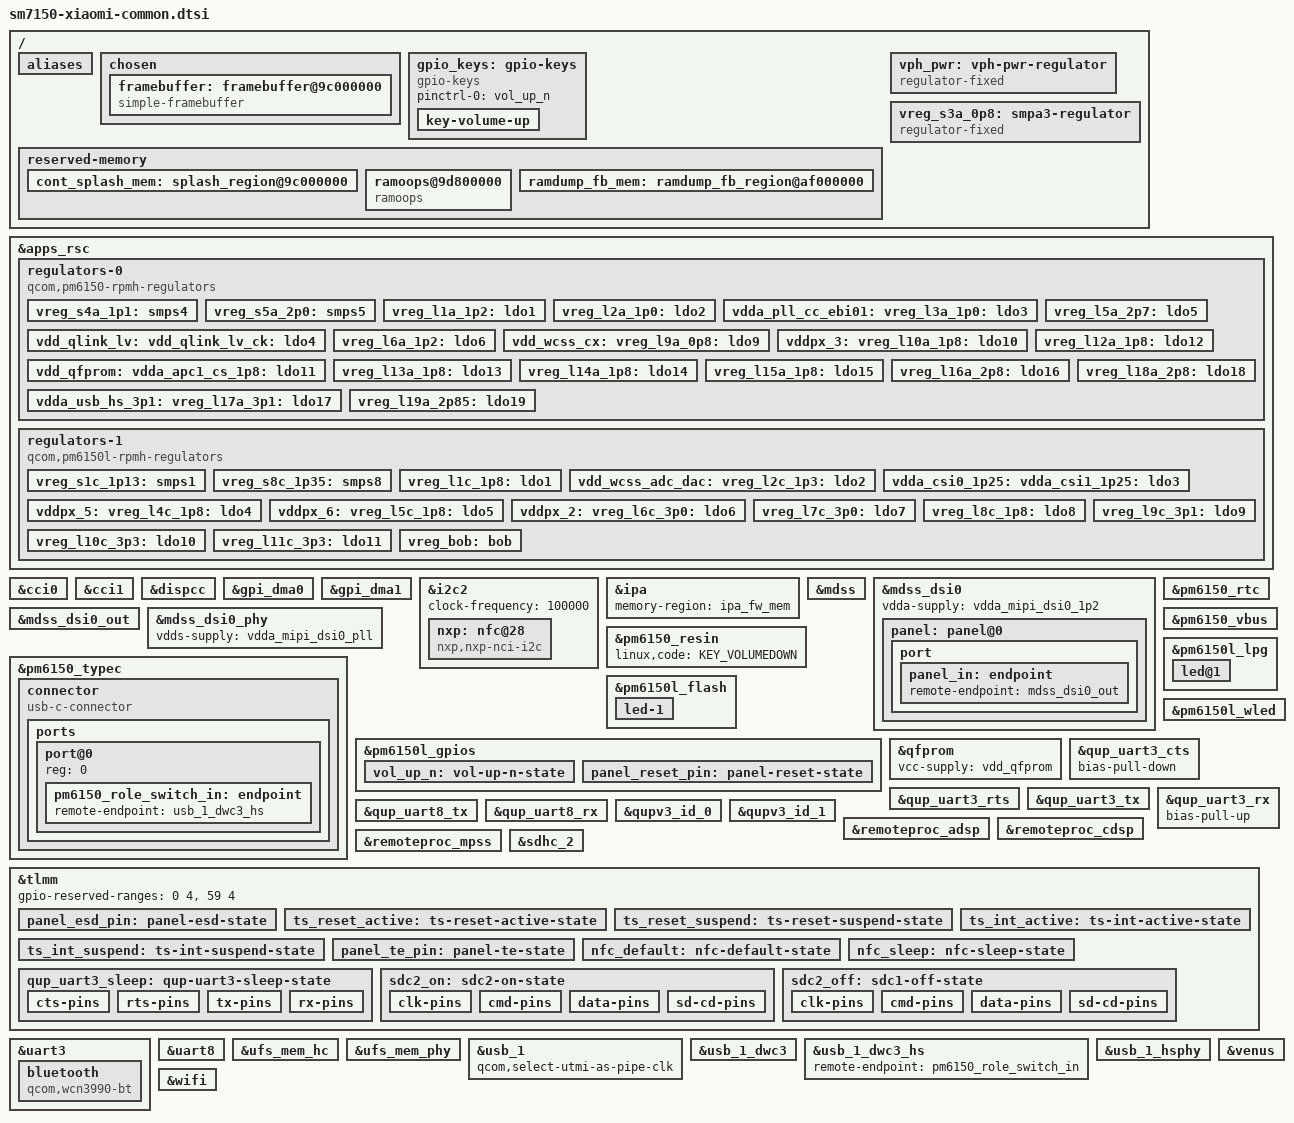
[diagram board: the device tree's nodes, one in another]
// SPDX-License-Identifier: BSD-3-Clause
/*
 * Copyright (c) 2024, Danila Tikhonov <danila@jiaxyga.com>
 * Copyright (c) 2024, David Wronek <davidwronek@gmail.com>
 * Copyright (c) 2024, Jens Reidel <adrian@travitia.xyz>
 */

/dts-v1/;

#include <dt-bindings/arm/qcom,ids.h>
#include <dt-bindings/firmware/qcom,scm.h>
#include <dt-bindings/gpio/gpio.h>
#include <dt-bindings/leds/common.h>
#include <dt-bindings/pinctrl/qcom,pmic-gpio.h>
#include <dt-bindings/regulator/qcom,rpmh-regulator.h>
#include <dt-bindings/sound/qcom,q6asm.h>
#include <dt-bindings/usb/pd.h>

#include "sm7150.dtsi"
#include "pm6150.dtsi"
#include "pm6150l.dtsi"

/ {
	chassis-type = "handset";

	qcom,msm-id = <QCOM_ID_SM7150 0>;

	aliases {
		bluetooth0 = &bluetooth;
		hsuart0 = &uart3;
		serial0 = &uart8;
		wifi0 = &wifi;
	};

	chosen {
		#address-cells = <2>;
		#size-cells = <2>;
		ranges;

		stdout-path = "serial0:115200n8";
		bootargs = "earlycon console=ttyMSM0,115200";

		framebuffer: framebuffer@9c000000 {
			compatible = "simple-framebuffer";
			reg = <0x0 0x9c000000 0x0 (1080 * 2400 * 4)>;
			width = <1080>;
			height = <2400>;
			stride = <(1080 * 4)>;
			format = "a8r8g8b8";

			display = <&panel>;

			clocks = <&gcc GCC_DISP_HF_AXI_CLK>;
		};
	};

	gpio_keys: gpio-keys {
		compatible = "gpio-keys";
		pinctrl-names = "default";
		pinctrl-0 = <&vol_up_n>;

		key-volume-up {
			label = "Volume Up";
			linux,code = <KEY_VOLUMEUP>;
			gpios = <&pm6150l_gpios 2 GPIO_ACTIVE_LOW>;
			debounce-interval = <15>;
		};
	};

	reserved-memory {
		cont_splash_mem: splash_region@9c000000 {
			reg = <0x0 0x9c000000 0x0 (1080 * 2400 * 4)>;
			no-map;
		};

		ramoops@9d800000 {
			compatible = "ramoops";
			reg = <0x0 0x9d800000 0x0 0x400000>;

			record-size = <0x80000>;
			pmsg-size = <0x200000>;
			console-size = <0x100000>;
		};

		ramdump_fb_mem: ramdump_fb_region@af000000 {
			reg = <0x0 0xaf000000 0x0 0x1000000>;
			no-map;
		};
	};

	vph_pwr: vph-pwr-regulator {
		compatible = "regulator-fixed";
		regulator-name = "vph_pwr";
		regulator-min-microvolt = <3700000>;
		regulator-max-microvolt = <3700000>;
	};

	// S3A is really mx.lvl but it's there for supply map completeness sake.
	vreg_s3a_0p8: smpa3-regulator {
		compatible = "regulator-fixed";
		regulator-name = "vreg_s3a_0p8";

		regulator-min-microvolt = <800000>;
		regulator-max-microvolt = <800000>;
		regulator-always-on;
		vin-supply = <&vph_pwr>;
	};
};

&apps_rsc {
	regulators-0 {
		compatible = "qcom,pm6150-rpmh-regulators";
		qcom,pmic-id = "a";

		vdd-s1-supply = <&vph_pwr>;
		vdd-s2-supply = <&vph_pwr>;
		vdd-s3-supply = <&vph_pwr>;
		vdd-s4-supply = <&vph_pwr>;
		vdd-s5-supply = <&vph_pwr>;

		vdd-l1-supply = <&vreg_s8c_1p35>;
		vdd-l2-l3-supply = <&vreg_s4a_1p1>;
		vdd-l4-l7-l8-supply = <&vreg_s4a_1p1>;
		vdd-l5-l16-l17-l18-l19-supply = <&vreg_bob>;
		vdd-l6-supply = <&vreg_s8c_1p35>;
		vdd-l9-supply = <&vreg_s3a_0p8>;
		vdd-l10-l14-l15-supply = <&vreg_s5a_2p0>;
		vdd-l11-l12-l13-supply = <&vreg_s5a_2p0>;

		/*
		 * S1 are unused.
		 * S2-S3, L7-L8 are ARCs:
		 * S2 - gfx.lvl,
		 * S3 - mx.lvl,
		 * L7 - lmx.lvl,
		 * L8 - lcx.lvl.
		 */

		vreg_s4a_1p1: smps4 {
			regulator-min-microvolt = <824000>;
			regulator-max-microvolt = <1120000>;
		};

		vreg_s5a_2p0: smps5 {
			regulator-min-microvolt = <1744000>;
			regulator-max-microvolt = <2040000>;
		};

		vreg_l1a_1p2: ldo1 {
			regulator-min-microvolt = <1096000>;
			regulator-max-microvolt = <1304000>;
			regulator-initial-mode = <RPMH_REGULATOR_MODE_HPM>;
		};

		vreg_l2a_1p0: ldo2 {
			regulator-min-microvolt = <944000>;
			regulator-max-microvolt = <1056000>;
			regulator-initial-mode = <RPMH_REGULATOR_MODE_HPM>;
		};

		vdda_pll_cc_ebi01:
		vreg_l3a_1p0: ldo3 {
			regulator-min-microvolt = <968000>;
			regulator-max-microvolt = <1064000>;
			regulator-initial-mode = <RPMH_REGULATOR_MODE_HPM>;
		};

		vdd_qlink_lv:
		vdd_qlink_lv_ck:
		vdd_usb_hs_core:
		vdda_mipi_csi0_0p9:
		vdda_mipi_csi1_0p9:
		vdda_mipi_csi2_0p9:
		vdda_mipi_csi3_0p9:
		vdda_mipi_dsi0_pll:
		vdda_mipi_dsi1_pll:
		vdda_qrefs_0p9:
		vdda_ufs_core:
		vdda_usb_ss_dp_core:
		vreg_l4a_0p88: ldo4 {
			regulator-min-microvolt = <824000>;
			regulator-max-microvolt = <920000>;
			regulator-initial-mode = <RPMH_REGULATOR_MODE_HPM>;
			regulator-allow-set-load;
			regulator-allowed-modes = <RPMH_REGULATOR_MODE_LPM
						   RPMH_REGULATOR_MODE_HPM>;
		};

		vreg_l5a_2p7: ldo5 {
			regulator-min-microvolt = <2600000>;
			regulator-max-microvolt = <2800000>;
			regulator-initial-mode = <RPMH_REGULATOR_MODE_HPM>;
		};

		vreg_l6a_1p2: ldo6 {
			regulator-min-microvolt = <1096000>;
			regulator-max-microvolt = <1304000>;
			regulator-initial-mode = <RPMH_REGULATOR_MODE_HPM>;
		};

		vdd_wcss_cx:
		vreg_l9a_0p8: ldo9 {
			regulator-min-microvolt = <624000>;
			regulator-max-microvolt = <760000>;
			regulator-initial-mode = <RPMH_REGULATOR_MODE_HPM>;
		};

		vddpx_3:
		vreg_l10a_1p8: ldo10 {
			regulator-min-microvolt = <1720000>;
			regulator-max-microvolt = <1832000>;
			regulator-initial-mode = <RPMH_REGULATOR_MODE_HPM>;
		};

		vdd_qfprom:
		vdda_apc1_cs_1p8:
		vdda_qrefs_1p8:
		vdda_usb_hs_1p8:
		vddpx_11:
		vreg_l11a_1p8: ldo11 {
			regulator-min-microvolt = <1696000>;
			regulator-max-microvolt = <1984000>;
			regulator-initial-mode = <RPMH_REGULATOR_MODE_HPM>;
		};

		vreg_l12a_1p8: ldo12 {
			regulator-min-microvolt = <1696000>;
			regulator-max-microvolt = <1952000>;
			regulator-initial-mode = <RPMH_REGULATOR_MODE_HPM>;
			regulator-allow-set-load;
			regulator-allowed-modes = <RPMH_REGULATOR_MODE_LPM
						   RPMH_REGULATOR_MODE_HPM>;
		};

		vreg_l13a_1p8: ldo13 {
			regulator-min-microvolt = <1696000>;
			regulator-max-microvolt = <1904000>;
			regulator-initial-mode = <RPMH_REGULATOR_MODE_HPM>;
		};

		vreg_l14a_1p8: ldo14 {
			regulator-min-microvolt = <1720000>;
			regulator-max-microvolt = <1856000>;
			regulator-initial-mode = <RPMH_REGULATOR_MODE_HPM>;
		};

		vreg_l15a_1p8: ldo15 {
			regulator-min-microvolt = <1696000>;
			regulator-max-microvolt = <1904000>;
			regulator-initial-mode = <RPMH_REGULATOR_MODE_HPM>;
		};

		vreg_l16a_2p8: ldo16 {
			regulator-min-microvolt = <1800000>;
			regulator-max-microvolt = <1800000>;
			regulator-initial-mode = <RPMH_REGULATOR_MODE_HPM>;
		};

		vdda_usb_hs_3p1:
		vreg_l17a_3p1: ldo17 {
			regulator-min-microvolt = <3000000>;
			regulator-max-microvolt = <3232000>;
			regulator-initial-mode = <RPMH_REGULATOR_MODE_HPM>;
		};

		vreg_l18a_2p8: ldo18 {
			regulator-min-microvolt = <3000000>;
			regulator-max-microvolt = <3000000>;
			regulator-initial-mode = <RPMH_REGULATOR_MODE_HPM>;
		};

		vreg_l19a_2p85: ldo19 {
			regulator-min-microvolt = <2944000>;
			regulator-max-microvolt = <3304000>;
			regulator-initial-mode = <RPMH_REGULATOR_MODE_HPM>;
			regulator-allow-set-load;
			regulator-allowed-modes = <RPMH_REGULATOR_MODE_LPM
						   RPMH_REGULATOR_MODE_HPM>;
		};
	};

	regulators-1 {
		compatible = "qcom,pm6150l-rpmh-regulators";
		qcom,pmic-id = "c";

		vdd-s1-supply = <&vph_pwr>;
		vdd-s2-supply = <&vph_pwr>;
		vdd-s3-supply = <&vph_pwr>;
		vdd-s4-supply = <&vph_pwr>;
		vdd-s5-supply = <&vph_pwr>;
		vdd-s6-supply = <&vph_pwr>;
		vdd-s7-supply = <&vph_pwr>;
		vdd-s8-supply = <&vph_pwr>;

		/*
		 * There should be:
		 * vdd-l1-l8-supply = <&vreg_s5a_2p0>;
		 * But pm7150l doesn't have access to S5A.
		 */
		vdd-l2-l3-supply = <&vreg_s8c_1p35>;
		vdd-l4-l5-l6-supply = <&vreg_bob>;
		vdd-l7-l11-supply = <&vreg_bob>;
		vdd-l9-l10-supply = <&vreg_bob>;

		vdd-bob-supply = <&vph_pwr>;
		vdd-flash-supply = <&vreg_bob>;
		vdd-rgb-supply = <&vreg_bob>;

		/*
		 * S4, S5 are unused.
		 * S2, S3, S7 are ARCs:
		 * S2-S3 - cx.lvl,
		 * S7 - mss.lvl.
		 */

		vreg_s1c_1p13: smps1 {
			regulator-min-microvolt = <1000000>;
			regulator-max-microvolt = <1200000>;
		};

		vreg_s8c_1p35: smps8 {
			regulator-min-microvolt = <1120000>;
			regulator-max-microvolt = <1408000>;
		};

		vreg_l1c_1p8: ldo1 {
			regulator-min-microvolt = <1616000>;
			regulator-max-microvolt = <1984000>;
			regulator-initial-mode = <RPMH_REGULATOR_MODE_HPM>;
		};

		vdd_wcss_adc_dac:
		vreg_l2c_1p3: ldo2 {
			regulator-min-microvolt = <1200000>;
			regulator-max-microvolt = <1352000>;
			regulator-initial-mode = <RPMH_REGULATOR_MODE_HPM>;
		};

		vdda_csi0_1p25:
		vdda_csi1_1p25:
		vdda_csi2_1p25:
		vdda_csi3_1p25:
		vdda_hv_ebi0:
		vdda_mipi_dsi0_1p2:
		vdda_mipi_dsi1_1p2:
		vdda_ufs_1p2:
		vdda_usb_ss_dp_1p2:
		vddpx_10:
		vreg_l3c_1p23: ldo3 {
			regulator-min-microvolt = <1144000>;
			regulator-max-microvolt = <1256000>;
			regulator-initial-mode = <RPMH_REGULATOR_MODE_HPM>;
			regulator-allow-set-load;
			regulator-allowed-modes = <RPMH_REGULATOR_MODE_LPM
						   RPMH_REGULATOR_MODE_HPM>;
		};

		vddpx_5:
		vreg_l4c_1p8: ldo4 {
			regulator-min-microvolt = <1648000>;
			regulator-max-microvolt = <2950000>;
			regulator-initial-mode = <RPMH_REGULATOR_MODE_HPM>;
		};

		vddpx_6:
		vreg_l5c_1p8: ldo5 {
			regulator-min-microvolt = <1648000>;
			regulator-max-microvolt = <2950000>;
			regulator-initial-mode = <RPMH_REGULATOR_MODE_HPM>;
		};

		vddpx_2:
		vreg_l6c_3p0: ldo6 {
			regulator-min-microvolt = <1648000>;
			regulator-max-microvolt = <3100000>;
			regulator-initial-mode = <RPMH_REGULATOR_MODE_HPM>;
			regulator-allow-set-load;
			regulator-allowed-modes = <RPMH_REGULATOR_MODE_LPM
						   RPMH_REGULATOR_MODE_HPM>;
		};

		vreg_l7c_3p0: ldo7 {
			regulator-min-microvolt = <3000000>;
			regulator-max-microvolt = <3312000>;
			regulator-initial-mode = <RPMH_REGULATOR_MODE_HPM>;
		};

		vreg_l8c_1p8: ldo8 {
			regulator-min-microvolt = <1800000>;
			regulator-max-microvolt = <1900000>;
			regulator-initial-mode = <RPMH_REGULATOR_MODE_HPM>;
		};

		/*
		 * Downstream specifies a range of 2950-3312mV.
		 * Tighten the range to 2950-3100mV.
		 */
		vreg_l9c_3p1: ldo9 {
			regulator-min-microvolt = <2950000>;
			regulator-max-microvolt = <3100000>;
			regulator-initial-mode = <RPMH_REGULATOR_MODE_HPM>;
			regulator-allow-set-load;
			regulator-allowed-modes = <RPMH_REGULATOR_MODE_LPM
						   RPMH_REGULATOR_MODE_HPM>;
		};

		vreg_l10c_3p3: ldo10 {
			regulator-min-microvolt = <3200000>;
			regulator-max-microvolt = <3312000>;
			regulator-initial-mode = <RPMH_REGULATOR_MODE_HPM>;
		};

		vreg_l11c_3p3: ldo11 {
			regulator-min-microvolt = <2950000>;
			regulator-max-microvolt = <3400000>;
			regulator-initial-mode = <RPMH_REGULATOR_MODE_HPM>;
		};

		vreg_bob: bob {
			regulator-min-microvolt = <3296000>;
			regulator-max-microvolt = <3960000>;
			regulator-initial-mode = <RPMH_REGULATOR_MODE_AUTO>;
			regulator-allow-bypass;
		};
	};
};

&cci0 {
	status = "okay";
};

&cci1 {
	status = "okay";
};

&dispcc {
	status = "okay";
};

&gpi_dma0 {
	status = "okay";
};

&gpi_dma1 {
	status = "okay";
};

&i2c2 {
	clock-frequency = <100000>;
	status = "okay";

	nxp: nfc@28 {
		compatible = "nxp,nxp-nci-i2c";

		reg = <0x28>;

		interrupt-parent = <&tlmm>;
		interrupts = <37 IRQ_TYPE_LEVEL_HIGH>;

		enable-gpios = <&tlmm 12 GPIO_ACTIVE_HIGH>;
		firmware-gpios = <&tlmm 36 GPIO_ACTIVE_HIGH>;

		pinctrl-names = "default", "sleep";
		pinctrl-0 = <&nfc_default>;
		pinctrl-1 = <&nfc_sleep>;
	};
};

&ipa {
	memory-region = <&ipa_fw_mem>;
	status = "okay";
};

&mdss {
	status = "okay";
};

&mdss_dsi0 {
	vdda-supply = <&vdda_mipi_dsi0_1p2>;
	status = "okay";

	panel: panel@0 {
		reg = <0>;

		vddio-supply = <&vreg_l13a_1p8>;
		vdd3p3-supply = <&vreg_l18a_2p8>;

		reset-gpios = <&pm6150l_gpios 9 GPIO_ACTIVE_LOW>;

		pinctrl-0 = <&panel_reset_pin &panel_te_pin>;
		pinctrl-names = "default";

		port {
			panel_in: endpoint {
				remote-endpoint = <&mdss_dsi0_out>;
			};
		};
	};
};

&mdss_dsi0_out {
	data-lanes = <0 1 2 3>;
	remote-endpoint = <&panel_in>;
	status = "okay";
};

&mdss_dsi0_phy {
	vdds-supply = <&vdda_mipi_dsi0_pll>;
	status = "okay";
};

&pm6150_resin {
	linux,code = <KEY_VOLUMEDOWN>;
	status = "okay";
};

&pm6150_rtc {
	status = "okay";
};

&pm6150_typec {
	vdd-vbus-supply = <&pm6150_vbus>;
	vdd-pdphy-supply = <&vdda_usb_hs_3p1>;
	status = "okay";

	connector {
		compatible = "usb-c-connector";

		power-role = "source";
		data-role = "dual";
		self-powered;

		source-pdos = <PDO_FIXED(5000, 3000, PDO_FIXED_DUAL_ROLE |
			       PDO_FIXED_USB_COMM | PDO_FIXED_DATA_SWAP)>;

		ports {
			#address-cells = <1>;
			#size-cells = <0>;

			port@0 {
				reg = <0>;
				pm6150_role_switch_in: endpoint {
					remote-endpoint = <&usb_1_dwc3_hs>;
				};
			};
		};
	};
};

&pm6150_vbus {
	regulator-min-microamp = <500000>;
	regulator-max-microamp = <3000000>;
	status = "okay";
};

&pm6150l_flash {
	led-1 {
		function = LED_FUNCTION_FLASH;
		color = <LED_COLOR_ID_WHITE>;
		led-sources = <1>;
		led-max-microamp = <150000>;
		flash-max-microamp = <1000000>;
		flash-max-timeout-us = <1280000>;
	};
};

&pm6150l_gpios {
	vol_up_n: vol-up-n-state {
		pins = "gpio2";
		function = PMIC_GPIO_FUNC_NORMAL;
		input-enable;
		bias-pull-up;
		power-source = <0>;
	};

	panel_reset_pin: panel-reset-state {
		pins = "gpio9";
		function = PMIC_GPIO_FUNC_FUNC1;
		qcom,drive-strength = <PMIC_GPIO_STRENGTH_MED>;
		bias-disable;
		output-low;
		power-source = <1>;
	};
};

&pm6150l_lpg {
	led@1 {
		reg = <1>;
		color = <LED_COLOR_ID_WHITE>;
		function = LED_FUNCTION_STATUS;
	};
};

&pm6150l_wled {
	qcom,cabc;
	qcom,cabc-sel = <1>;
	qcom,num-strings = <3>;
};

&qfprom {
	vcc-supply = <&vdd_qfprom>;
};

&qup_uart3_cts {
	bias-pull-down;
};

&qup_uart3_rts {
	drive-strength = <2>;
	bias-disable;
};

&qup_uart3_tx {
	drive-strength = <2>;
	bias-disable;
};

&qup_uart3_rx {
	bias-pull-up;
};

&qup_uart8_tx {
	drive-strength = <2>;
	bias-disable;
};

&qup_uart8_rx {
	drive-strength = <2>;
	bias-pull-up;
};

&qupv3_id_0 {
	status = "okay";
};

&qupv3_id_1 {
	status = "okay";
};

&remoteproc_adsp {
	status = "okay";
};

&remoteproc_cdsp {
	status = "okay";
};

&remoteproc_mpss {
	status = "okay";
};

&sdhc_2 {
	cd-gpios = <&tlmm 69 GPIO_ACTIVE_HIGH>;

	vmmc-supply = <&vreg_l9c_3p1>;
	vqmmc-supply = <&vreg_l6c_3p0>;

	pinctrl-names = "default", "sleep";
	pinctrl-0 = <&sdc2_on>;
	pinctrl-1 = <&sdc2_off>;
};

&tlmm {
	/* Reserved I/Os for NFC and FP */
	gpio-reserved-ranges = <0 4>, <59 4>;

	panel_esd_pin: panel-esd-state {
		pins = "gpio4";
		function = "gpio";
		drive-strength = <2>;
		bias-pull-down;
	};

	ts_reset_active: ts-reset-active-state {
		pins = "gpio8";
		function = "gpio";
		drive-strength = <16>;
		bias-pull-up;
	};

	ts_reset_suspend: ts-reset-suspend-state {
		pins = "gpio8";
		function = "gpio";
		drive-strength = <16>;
		bias-disable;
		output-high;
	};

	ts_int_active: ts-int-active-state {
		pins = "gpio9";
		function = "gpio";
		drive-strength = <16>;
		bias-pull-up;
	};

	ts_int_suspend: ts-int-suspend-state {
		pins = "gpio9";
		function = "gpio";
		drive-strength = <16>;
		input-enable;
		bias-disable;
	};

	panel_te_pin: panel-te-state {
		pins = "gpio10";
		function = "mdp_vsync";
		drive-strength = <2>;
		bias-pull-down;
	};

	nfc_default: nfc-default-state {
		pins = "gpio12", "gpio31", "gpio36";
		function = "gpio";
		drive-strength = <2>;
		bias-pull-up;
	};

	nfc_sleep: nfc-sleep-state {
		pins = "gpio12", "gpio31", "gpio36";
		function = "gpio";
		drive-strength = <2>;
		bias-disable;
	};

	qup_uart3_sleep: qup-uart3-sleep-state {
		cts-pins {
			pins = "gpio38";
			function = "gpio";
			bias-pull-down;
		};

		rts-pins {
			pins = "gpio39";
			function = "gpio";
			bias-pull-down;
		};

		tx-pins {
			pins = "gpio40";
			function = "gpio";
			bias-pull-up;
		};

		rx-pins {
			pins = "gpio41";
			function = "gpio";
			bias-pull-up;
		};
	};

	sdc2_on: sdc2-on-state {
		clk-pins {
			pins = "sdc2_clk";
			bias-disable;
			drive-strength = <16>;
		};

		cmd-pins {
			pins = "sdc2_cmd";
			bias-pull-up;
			drive-strength = <10>;
		};

		data-pins {
			pins = "sdc2_data";
			bias-pull-up;
			drive-strength = <10>;
		};

		sd-cd-pins {
			pins = "gpio69";
			function = "gpio";
			bias-pull-up;
			drive-strength = <2>;
		};
	};

	sdc2_off: sdc1-off-state {
		clk-pins {
			pins = "sdc2_clk";
			bias-disable;
			drive-strength = <2>;
		};

		cmd-pins {
			pins = "sdc2_cmd";
			bias-pull-up;
			drive-strength = <2>;
		};

		data-pins {
			pins = "sdc2_data";
			bias-pull-up;
			drive-strength = <2>;
		};

		sd-cd-pins {
			pins = "gpio69";
			function = "gpio";
			bias-pull-up;
			drive-strength = <2>;
		};
	};
};

&uart3 {
	/delete-property/interrupts;
	interrupts-extended = <&intc GIC_SPI 604 IRQ_TYPE_LEVEL_HIGH>,
			      <&tlmm 41 IRQ_TYPE_EDGE_FALLING>;

	pinctrl-names = "default", "sleep";
	pinctrl-1 = <&qup_uart3_sleep>;
	status = "okay";

	bluetooth: bluetooth {
		compatible = "qcom,wcn3990-bt";

		vddio-supply = <&vreg_l10a_1p8>;
		vddxo-supply = <&vreg_l1c_1p8>;
		vddrf-supply = <&vdd_wcss_adc_dac>;
		vddch0-supply = <&vreg_l10c_3p3>;
		max-speed = <3200000>;
	};
};

&uart8 {
	status = "okay";
};

&ufs_mem_hc {
	reset-gpios = <&tlmm 119 GPIO_ACTIVE_LOW>;

	vcc-supply = <&vreg_l19a_2p85>;
	vcc-max-microamp = <600000>;
	vccq2-supply = <&vreg_l12a_1p8>;
	vccq2-max-microamp = <600000>;
	status = "okay";
};

&ufs_mem_phy {
	vdda-phy-supply = <&vdda_ufs_core>;
	vdda-pll-supply = <&vdda_ufs_1p2>;
	status = "okay";
};

&usb_1 {
	qcom,select-utmi-as-pipe-clk;
	status = "okay";
};

&usb_1_dwc3 {
	dr_mode = "otg";
	usb-role-switch;
	maximum-speed = "high-speed";
};

&usb_1_dwc3_hs {
	remote-endpoint = <&pm6150_role_switch_in>;
};

&usb_1_hsphy {
	vdd-supply = <&vdd_usb_hs_core>;
	vdda-pll-supply = <&vdda_usb_hs_1p8>;
	vdda-phy-dpdm-supply = <&vdda_usb_hs_3p1>;
	status = "okay";
};

&venus {
	//status = "okay";
};

&wifi {
	vdd-0.8-cx-mx-supply = <&vdd_wcss_cx>;
	vdd-1.8-xo-supply = <&vreg_l1c_1p8>;
	vdd-1.3-rfa-supply = <&vdd_wcss_adc_dac>;
	vdd-3.3-ch0-supply = <&vreg_l10c_3p3>;
	vdd-3.3-ch1-supply = <&vreg_l11c_3p3>;
	status = "okay";
};
